# L1_SCACHE register map
Vendor: Texas Instruments
Peripheral module from a debugger description file (folder omap5430_ES2_PUBLIC).
Registers are 32-bit, read-write, reset 0x0 unless marked. A register's access mark holds for its fields unless they carry their own. Offsets are as the file gives them; lines under a group give offsets from that group; [hi:lo] are bit positions; {n}, {i} and the like mark numbered series; 'fields as' and 'values as' point back to an identical list; <NAME> marks a mode.

## L1_SCACHE
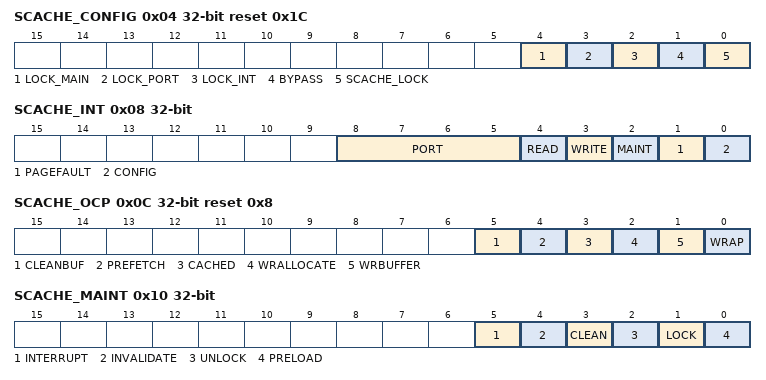
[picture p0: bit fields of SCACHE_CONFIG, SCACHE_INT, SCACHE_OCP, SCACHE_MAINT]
0x04 SCACHE_CONFIG access per field reset 0x1C — Configuration Register
  [4] LOCK_MAIN rw — Lock access to maintenance registers
    0=Locked; 1=Not_locked
  [3] LOCK_PORT rw — Lock access to interface registers
    0=Locked; 1=Not_locked
  [2] LOCK_INT rw — Lock access to interrupt registers
    0=Locked; 1=Not_locked
  [1] BYPASS rw — Bypass cache
    0=Everything_is_non-cacheable; 1=Everything_is_cacheable
  [0] SCACHE_LOCK rw — SCACHE lock. Once this bit is set only debugger or hardware reset can clear.
    0=No_effect; 1=Only_debug_accesses_allowed
0x08 SCACHE_INT access not given — Interrupt Register
  [8:5] PORT — slave interface number that has recorded an error (access RW W1toClr)
  [4] READ — interface read response error (access RW W1toClr)
  [3] WRITE — interface write response error (access RW W1toClr)
  [2] MAINT — maintenance is completed (access RW W1toClr)
  [1] PAGEFAULT — AMMU page fault (access RW W1toClr)
  [0] CONFIG — configuration error (access RW W1toClr)
0x0C SCACHE_OCP access per field reset 0x8 — Interface Configuration Register
  [5] CLEANBUF rw — clean write and prefetch buffers in cache
    0=do_not_clean; 1=clean
  [4] PREFETCH rw — always prefetch data
    0=follow_MMU_policies; 1=always_prefetch
  [3] CACHED rw — follow cacheable sideband signals
    0=reads always not allocated, writes write through if cached; 1=slave_sideband_signals_determine_policy
  [2] WRALLOCATE rw — follow write allocate sideband signals
    0=no writes are allocated independent to sideband; 1=follow_sideband
  [1] WRBUFFER rw — write throughs and write back no allocate are buffered
    0=write throughs and write back no allocated are not buffered; 1=write throughs and write back no allocated are buffered
  [0] WRAP rw — OCP wrap mode (critical word first)
    0=disabled; 1=enabled
0x10 SCACHE_MAINT access per field — Maintenance Configuration Register
  [5] INTERRUPT rw — generate interrupt when maintenance operation is complete
    0=do_not_generate_interrupt; 1=generate_interrupt
  [4] INVALIDATE rw — invalidate lines in region defined by maintenance start/end addresses
    0=do_nothing; 1=invalidate
  [3] CLEAN rw — evict dirty lines in region defined by maintenance start/end addresses
    0=do_nothing; 1=clean
  [2] UNLOCK rw — unlock region defined by maintenance start/end addresses
    0=do_nothing; 1=unlock
  [1] LOCK rw — lock region defined by maintenance start/end addresses
    0=do_nothing; 1=lock
  [0] PRELOAD rw — preload region defined by maintenance start/end addresses
    0=do_nothing; 1=preload
0x14 SCACHE_MTSTART — Maintenance Start Configuration Register
  [31:0] START_ADDR — start address of maintenance operations, reset to 0x0000 when finished
0x18 SCACHE_MTEND — Maintenance End Configuration Register
  [31:0] END_ADDR — end address of maintenance operations, resets to 0x0000 when finished
0x1C SCACHE_CTADDR — Cache Test Address Register
  [31:0] ADDRESS — address of cache visibility when read CTDATA register, autoincrements
0x20 SCACHE_CTDATA — Cache Test Data Register
  [31:0] DATA — cache data at address of CTADDR register, CTADDR autoincrements each time CTDATA is read
